# COMPUTE_CLUSTER0_DRU_MMR_DRU0_MMR_CFG_DRU_SET register map
Vendor: Texas Instruments
Peripheral module from a debugger description file (folder J721S2).
Registers are 64-bit, write-only, reset 0x0 unless marked. A register's access mark holds for its fields unless they carry their own. Offsets are as the file gives them; lines under a group give offsets from that group; [hi:lo] are bit positions; {n}, {i} and the like mark numbered series; 'fields as' and 'values as' point back to an identical list; <NAME> marks a mode.

## COMPUTE_CLUSTER0_DRU_MMR_DRU0_MMR_CFG_DRU_SET
0x00 MMR__DRU0_MMR_CFG__DRU_SET_dru_shared_evt_set — DRU Shared Event Set Register
  [0] PROT_ERR — Set the Prot Error event
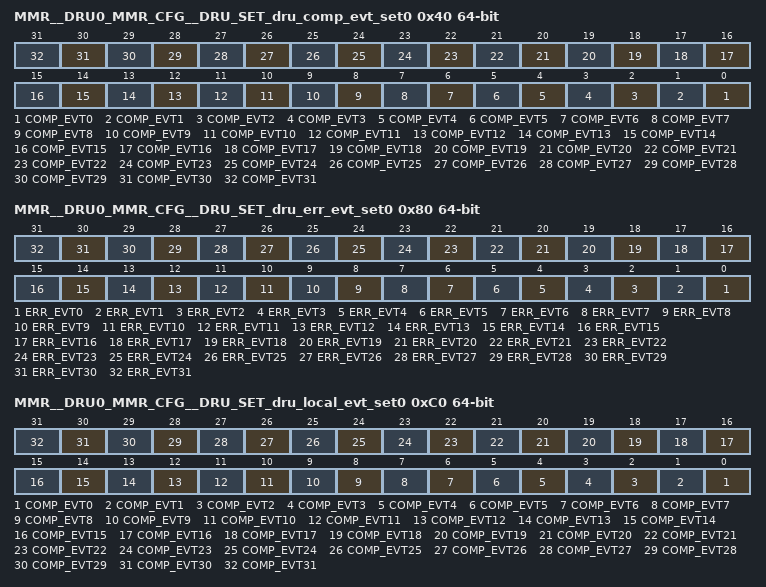
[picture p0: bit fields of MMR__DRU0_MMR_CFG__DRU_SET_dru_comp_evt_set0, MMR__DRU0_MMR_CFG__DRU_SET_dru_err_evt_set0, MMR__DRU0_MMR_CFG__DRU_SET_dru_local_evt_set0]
0x40 MMR__DRU0_MMR_CFG__DRU_SET_dru_comp_evt_set0 — DRU Completion Event Set Register
  [n] COMP_EVT{n} (n=0..31) — Set the Completion Event for channel {n}
0x80 MMR__DRU0_MMR_CFG__DRU_SET_dru_err_evt_set0 — DRU Error Event Set Register
  [n] ERR_EVT{n} (n=0..31) — Set the Error Event for channel {n}
0xC0 MMR__DRU0_MMR_CFG__DRU_SET_dru_local_evt_set0 — DRU Local Event Set Register
  [n] COMP_EVT{n} (n=0..31) — Set the Local Event for channel {n}
